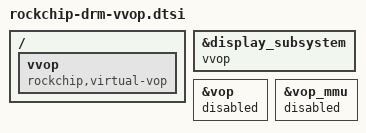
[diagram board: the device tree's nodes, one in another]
/**
 * Include this file if not real video ouput device but want a drm node (/dev/dri)
 */

/ {
	vvop: vvop {
		compatible = "rockchip,virtual-vop";
		status = "okay";
	};
};

&display_subsystem {
	vvop;
};

&vop {
	status = "disabled";
};

&vop_mmu {
	status = "disabled";
};
